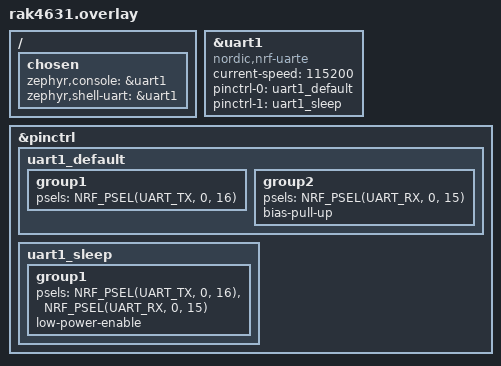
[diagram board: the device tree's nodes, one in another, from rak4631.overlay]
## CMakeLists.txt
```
cmake_minimum_required(VERSION 3.20.0)
find_package(Zephyr REQUIRED HINTS $ENV{ZEPHYR_BASE})
project(uart_test_target1)

target_sources(app PRIVATE src/main.c)
```

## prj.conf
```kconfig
# USB CDC ACM
CONFIG_USB_DEVICE_STACK=y
CONFIG_USB_DEVICE_PRODUCT="UART Test Target1"
CONFIG_USB_DEVICE_VID=0x2FE3
CONFIG_USB_DEVICE_PID=0x0001

# Serial/Console
CONFIG_SERIAL=y
CONFIG_CONSOLE=y
CONFIG_UART_CONSOLE=y
CONFIG_UART_LINE_CTRL=y

# USB Console
CONFIG_USB_DEVICE_INITIALIZE_AT_BOOT=y

# Logging
CONFIG_LOG=y
CONFIG_LOG_BACKEND_UART=y
CONFIG_LOG_DEFAULT_LEVEL=3

# Printk
CONFIG_PRINTK=y
```

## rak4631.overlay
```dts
/*
 * UART Test - RAK4631 Overlay
 * Debug UART: TX=P0.16, RX=P0.15
 */

/ {
	chosen {
		zephyr,console = &uart1;
		zephyr,shell-uart = &uart1;
	};
};

&uart1 {
	compatible = "nordic,nrf-uarte";
	status = "okay";
	current-speed = <115200>;
	pinctrl-0 = <&uart1_default>;
	pinctrl-1 = <&uart1_sleep>;
	pinctrl-names = "default", "sleep";
};

&pinctrl {
	uart1_default: uart1_default {
		group1 {
			psels = <NRF_PSEL(UART_TX, 0, 16)>;
		};
		group2 {
			psels = <NRF_PSEL(UART_RX, 0, 15)>;
			bias-pull-up;
		};
	};

	uart1_sleep: uart1_sleep {
		group1 {
			psels = <NRF_PSEL(UART_TX, 0, 16)>,
				<NRF_PSEL(UART_RX, 0, 15)>;
			low-power-enable;
		};
	};
};
```

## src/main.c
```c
#include <zephyr/kernel.h>
#include <zephyr/device.h>
#include <zephyr/drivers/uart.h>
#include <zephyr/usb/usb_device.h>
#include <stdio.h>

int main(void)
{
    int ret;
    uint32_t count = 0;

    /* Enable USB */
    ret = usb_enable(NULL);
    if (ret != 0 && ret != -EALREADY) {
        printk("USB enable failed: %d\n", ret);
    }

    /* Wait for USB to be ready */
    k_sleep(K_MSEC(2000));

    printk("\n========================================\n");
    printk("UART Test - REVITA Started\n");
    printk("RAK4631 via PCA10056 S/N: 1050295470\n");
    printk("========================================\n\n");

    while (1) {
        printk("revita: %u\n", count);
        count++;
        k_sleep(K_MSEC(1000));
    }

    return 0;
}
```
